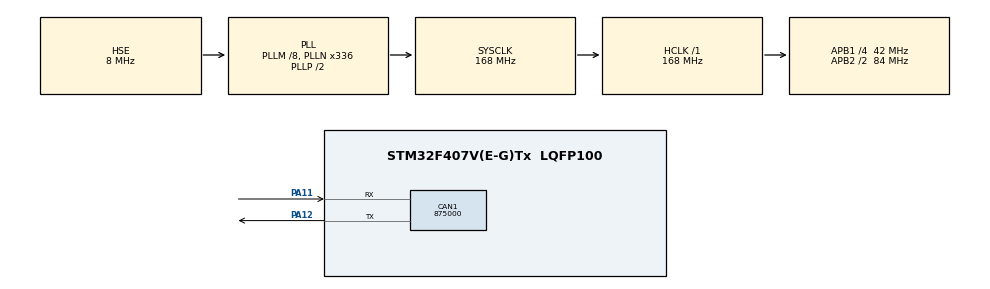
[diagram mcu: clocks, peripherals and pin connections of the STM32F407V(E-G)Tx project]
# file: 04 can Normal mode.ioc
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CAN1.CalculateBaudRate=875000
CAN1.CalculateTimeBit=1142
CAN1.CalculateTimeQuantum=380.95238095238096
Mcu.Family=STM32F4
Mcu.Name=STM32F407V(E-G)Tx
Mcu.Package=LQFP100
NVIC.CAN1_RX0_IRQn=true\:0\:0\:false\:false\:true\:true\:true\:true
NVIC.CAN1_SCE_IRQn=true\:0\:0\:false\:false\:true\:true\:true\:true
NVIC.CAN1_TX_IRQn=true\:0\:0\:false\:false\:true\:true\:true\:true
NVIC.PriorityGroup=NVIC_PRIORITYGROUP_0
NVIC.TIM6_DAC_IRQn=true\:0\:0\:false\:false\:true\:true\:true\:true
PA11.Mode=CAN_Activate
PA11.Signal=CAN1_RX
PA12.Mode=CAN_Activate
PA12.Signal=CAN1_TX
PA13.Mode=Serial_Wire
PA13.Signal=SYS_JTMS-SWDIO
PA14.Mode=Serial_Wire
PA14.Signal=SYS_JTCK-SWCLK
PH0-OSC_IN.Mode=HSE-External-Oscillator
PH0-OSC_IN.Signal=RCC_OSC_IN
PH1-OSC_OUT.Mode=HSE-External-Oscillator
PH1-OSC_OUT.Signal=RCC_OSC_OUT
ProjectManager.HeapSize=0x200
ProjectManager.StackSize=0x400
ProjectManager.TargetToolchain=MDK-ARM V5.32
RCC.48MHZClocksFreq_Value=48000000
RCC.AHBFreq_Value=168000000
RCC.APB1CLKDivider=RCC_HCLK_DIV4
RCC.APB1Freq_Value=42000000
RCC.APB1TimFreq_Value=84000000
RCC.APB2CLKDivider=RCC_HCLK_DIV2
RCC.APB2Freq_Value=84000000
RCC.APB2TimFreq_Value=168000000
RCC.CortexFreq_Value=168000000
RCC.HCLKFreq_Value=168000000
RCC.HSE_VALUE=8000000
RCC.HSI_VALUE=16000000
RCC.PLLM=8
RCC.PLLN=336
RCC.PLLQ=7
RCC.PLLSourceVirtual=RCC_PLLSOURCE_HSE
RCC.SYSCLKFreq_VALUE=168000000
RCC.SYSCLKSource=RCC_SYSCLKSOURCE_PLLCLK
RCC.VCOOutputFreq_Value=336000000
TIM6.Period=9999
TIM6.Prescaler=4999
VP_TIM6_VS_ClockSourceINT.Mode=Enable_Timer
board=STM32F407G-DISC1

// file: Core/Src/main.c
/* USER CODE BEGIN Header */
/**
  ******************************************************************************
  * @file           : main.c
  * @brief          : Main program body
  ******************************************************************************
  * @attention
  *
  * Copyright (c) 2024 STMicroelectronics.
  * All rights reserved.
  *
  * This software is licensed under terms that can be found in the LICENSE file
  * in the root directory of this software component.
  * If no LICENSE file comes with this software, it is provided AS-IS.
  *
  ******************************************************************************
  */
/* USER CODE END Header */
#include "main.h"

CAN_HandleTypeDef hcan1;

TIM_HandleTypeDef htim6;

void SystemClock_Config(void);
static void MX_GPIO_Init(void);
static void MX_CAN1_Init(void);
static void MX_TIM6_Init(void);

	void CAN1_Tx(void);
	void CAN1_Rx(void);
	void CAN1_FilterConfig(void);

int main(void)
{
  HAL_Init();
  SystemClock_Config();

  MX_GPIO_Init();
  MX_CAN1_Init();
  MX_TIM6_Init();

	CAN1_FilterConfig();

	// before CAN1 Start, Enable Interrupt
	if( HAL_CAN_ActivateNotification(&hcan1, CAN_IT_TX_MAILBOX_EMPTY | CAN_IT_RX_FIFO0_MSG_PENDING | CAN_IT_BUSOFF) != HAL_OK )
	{
		// Error_Handler();
	}

	if( HAL_CAN_Start(&hcan1) != HAL_OK ) { Error_Handler(); }

  while (1)
  {

  }

}

void SystemClock_Config(void)
{
  RCC_OscInitTypeDef RCC_OscInitStruct = {0};
  RCC_ClkInitTypeDef RCC_ClkInitStruct = {0};

  /** Configure the main internal regulator output voltage
  */
  __HAL_RCC_PWR_CLK_ENABLE();
  __HAL_PWR_VOLTAGESCALING_CONFIG(PWR_REGULATOR_VOLTAGE_SCALE1);

  /** Initializes the RCC Oscillators according to the specified parameters
  * in the RCC_OscInitTypeDef structure.
  */
  RCC_OscInitStruct.OscillatorType = RCC_OSCILLATORTYPE_HSE;
  RCC_OscInitStruct.HSEState = RCC_HSE_ON;
  RCC_OscInitStruct.PLL.PLLState = RCC_PLL_ON;
  RCC_OscInitStruct.PLL.PLLSource = RCC_PLLSOURCE_HSE;
  RCC_OscInitStruct.PLL.PLLM = 8;
  RCC_OscInitStruct.PLL.PLLN = 336;
  RCC_OscInitStruct.PLL.PLLP = RCC_PLLP_DIV2;
  RCC_OscInitStruct.PLL.PLLQ = 7;
  if (HAL_RCC_OscConfig(&RCC_OscInitStruct) != HAL_OK)
  {
    Error_Handler();
  }

  /** Initializes the CPU, AHB and APB buses clocks
  */
  RCC_ClkInitStruct.ClockType = RCC_CLOCKTYPE_HCLK|RCC_CLOCKTYPE_SYSCLK
                              |RCC_CLOCKTYPE_PCLK1|RCC_CLOCKTYPE_PCLK2;
  RCC_ClkInitStruct.SYSCLKSource = RCC_SYSCLKSOURCE_PLLCLK;
  RCC_ClkInitStruct.AHBCLKDivider = RCC_SYSCLK_DIV1;
  RCC_ClkInitStruct.APB1CLKDivider = RCC_HCLK_DIV4;
  RCC_ClkInitStruct.APB2CLKDivider = RCC_HCLK_DIV2;

  if (HAL_RCC_ClockConfig(&RCC_ClkInitStruct, FLASH_LATENCY_5) != HAL_OK)
  {
    Error_Handler();
  }
}

static void MX_CAN1_Init(void)
{
  hcan1.Instance = CAN1;
  hcan1.Init.Mode = CAN_MODE_NORMAL;
	hcan1.Init.AutoBusOff = ENABLE;
	hcan1.Init.AutoRetransmission = ENABLE;
	hcan1.Init.AutoWakeUp = DISABLE;
  hcan1.Init.ReceiveFifoLocked = DISABLE;
	hcan1.Init.TimeTriggeredMode = DISABLE;
	hcan1.Init.TransmitFifoPriority = DISABLE;

	// Setting Related to CAN bit timings
  hcan1.Init.Prescaler = 5;
  hcan1.Init.SyncJumpWidth = CAN_SJW_1TQ;
  hcan1.Init.TimeSeg1 = CAN_BS1_8TQ;
  hcan1.Init.TimeSeg2 = CAN_BS2_1TQ;

  if (HAL_CAN_Init(&hcan1) != HAL_OK)
  {
    Error_Handler();
  }

}

static void MX_TIM6_Init(void)
{

  TIM_MasterConfigTypeDef sMasterConfig = {0};

  htim6.Instance = TIM6;
  htim6.Init.Prescaler = 4999;
  htim6.Init.CounterMode = TIM_COUNTERMODE_UP;
  htim6.Init.Period = 9999;
  htim6.Init.AutoReloadPreload = TIM_AUTORELOAD_PRELOAD_DISABLE;
  if (HAL_TIM_Base_Init(&htim6) != HAL_OK)
  {
    Error_Handler();
  }
  sMasterConfig.MasterOutputTrigger = TIM_TRGO_RESET;
  sMasterConfig.MasterSlaveMode = TIM_MASTERSLAVEMODE_DISABLE;
  if (HAL_TIMEx_MasterConfigSynchronization(&htim6, &sMasterConfig) != HAL_OK)
  {
    Error_Handler();
  }

}

static void MX_GPIO_Init(void)
{

  /* GPIO Ports Clock Enable */
  __HAL_RCC_GPIOH_CLK_ENABLE();
  __HAL_RCC_GPIOA_CLK_ENABLE();

}

/* USER CODE BEGIN 4 */
void CAN1_Tx(void)
{
	uint32_t TxMailbox;
	uint8_t msg[11] = {'R','0','M',' ','D','y','n','a','m','i','c'};

	CAN_TxHeaderTypeDef TxHeader;
	TxHeader.DLC = 5;
	TxHeader.StdId = 0x45D;
	TxHeader.IDE = CAN_ID_STD;
	TxHeader.RTR = CAN_RTR_DATA;

	if( HAL_CAN_AddTxMessage(&hcan1, &TxHeader, msg, &TxMailbox) != HAL_OK)
	{
		Error_Handler();
	}

}
void CAN1_Rx(void)
{

}

void CAN1_FilterConfig(void)
{
	CAN_FilterTypeDef can1_filter;

	can1_filter.FilterActivation = ENABLE;
	can1_filter.FilterBank = 0;
	can1_filter.FilterFIFOAssignment = CAN_RX_FIFO0;
	can1_filter.FilterIdHigh = 0x0000;
	can1_filter.FilterIdLow = 0x0000;
	can1_filter.FilterMaskIdHigh = 0x0000;
	can1_filter.FilterMaskIdLow = 0x0000;
	can1_filter.FilterMode = CAN_FILTERMODE_IDMASK;
	can1_filter.FilterScale = CAN_FILTERSCALE_32BIT;

	if( HAL_CAN_ConfigFilter(&hcan1, &can1_filter) != HAL_OK )
	{
		Error_Handler();
	}

}

// Callback functions
void HAL_CAN_TxMailbox0CompleteCallback(CAN_HandleTypeDef *hcan)
{
	// printf()
}
void HAL_CAN_TxMailbox1CompleteCallback(CAN_HandleTypeDef *hcan)
{
	// printf()
}
void HAL_CAN_TxMailbox2CompleteCallback(CAN_HandleTypeDef *hcan)
{
	// printf()
}

void HAL_CAN_RxFifo0MsgPendingCallback(CAN_HandleTypeDef *hcan)
{
	CAN_RxHeaderTypeDef RxHeader;
	uint8_t rec_msg[11];

	if( HAL_CAN_GetRxMessage(&hcan1, CAN_RX_FIFO0, &RxHeader, rec_msg) != HAL_OK) {
		Error_Handler();
	}
}
void HAL_CAN_ErrorCallback(CAN_HandleTypeDef *hcan)
{
	// printf();
}

void HAL_TIM_PeriodElapsedCallback(TIM_HandleTypeDef *htim)
{
  /* Prevent unused argument(s) compilation warning */
  UNUSED(htim);
	// CAN Transmit 2:31
}
/* USER CODE END 4 */

void Error_Handler(void)
{
  __disable_irq();
  while (1)
  {
  }
}
